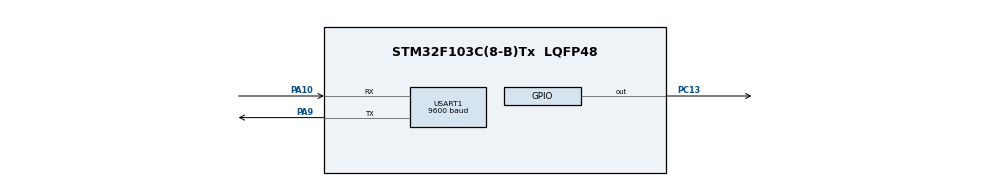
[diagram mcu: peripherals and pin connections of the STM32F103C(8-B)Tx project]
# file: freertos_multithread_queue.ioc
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FREERTOS.Tasks01=defaultTas,0,128,StartDefaultTask,Default,NULL,Dynamic,NULL,NULL
FREERTOS.configUSE_NEWLIB_REENTRANT=1
Mcu.Family=STM32F1
Mcu.Name=STM32F103C(8-B)Tx
Mcu.Package=LQFP48
NVIC.PriorityGroup=NVIC_PRIORITYGROUP_4
NVIC.USART1_IRQn=true\:5\:0\:false\:false\:true\:true\:true\:true\:true
PA10.Mode=Asynchronous
PA10.Signal=USART1_RX
PA13.Mode=Serial_Wire
PA13.Signal=SYS_JTMS-SWDIO
PA14.Mode=Serial_Wire
PA14.Signal=SYS_JTCK-SWCLK
PA9.Mode=Asynchronous
PA9.Signal=USART1_TX
PC13-TAMPER-RTC.Signal=GPIO_Output
ProjectManager.HeapSize=0x200
ProjectManager.StackSize=0x400
ProjectManager.TargetToolchain=STM32CubeIDE
RCC.APB1Freq_Value=8000000
RCC.APB2Freq_Value=8000000
USART1.BaudRate=9600
USART1.VirtualMode=VM_ASYNC
VP_FREERTOS_VS_CMSIS_V1.Mode=CMSIS_V1
board=custom

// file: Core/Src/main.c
/* USER CODE BEGIN Header */
/**
  ******************************************************************************
  * @file           : main.c
  * @brief          : Main program body
  ******************************************************************************
  * @attention
  *
  * Copyright (c) 2023 STMicroelectronics.
  * All rights reserved.
  *
  * This software is licensed under terms that can be found in the LICENSE file
  * in the root directory of this software component.
  * If no LICENSE file comes with this software, it is provided AS-IS.
  *
  ******************************************************************************
  */
/* USER CODE END Header */
#include "main.h"
#include "cmsis_os.h"
#include "usart.h"
#include "gpio.h"

/* USER CODE BEGIN Includes */
#include <string.h>
/* USER CODE END Includes */

/* USER CODE BEGIN PV */
volatile xQueueHandle serial_str_queue = NULL;
volatile xSemaphoreHandle serial_tx_wait_sem = NULL;
volatile xQueueHandle serial_rx_queue = NULL;

/* Queue structure used for passing messages. */
typedef struct
{
    char str[100];
} serial_str_msg;

/* Queue structure used for passing characters. */
typedef struct
{
    char ch;
} serial_ch_msg;

/* USER CODE END PV */

/* USER CODE BEGIN PFP */
void HAL_UART_TxCpltCallback(UART_HandleTypeDef *huart);
void HAL_UART_TxCpltCallback(UART_HandleTypeDef *huart);
void send_byte_rtos(char ch);
char receive_byte_rtos(void);
void led_flash_task( void *pvParameters );
void rs232_xmit_msg_task( void *pvParameters );
void queue_str_task(const char *str, int delay);
void queue_str_task1( void *pvParameters );
void queue_str_task2( void *pvParameters );
void serial_readwrite_task( void *pvParameters );

/* USER CODE END PFP */

int main(void)
{
  /* USER CODE BEGIN 1 */
	serial_ch_msg rx_msg;
  /* USER CODE END 1 */

  /* MCU Configuration--------------------------------------------------------*/

  /* Reset of all peripherals, Initializes the Flash interface and the Systick. */
  HAL_Init();

  /* Configure the system clock */
  SystemClock_Config();

  /* Initialize all configured peripherals */
  MX_GPIO_Init();
  MX_USART1_UART_Init();
  /* USER CODE BEGIN 2 */
  HAL_UART_Receive_IT(&huart1,(void *)&(rx_msg.ch), sizeof(rx_msg.ch));

  /* Create the queue to hold messages to be written to the RS232. */
  serial_str_queue = xQueueCreate( 10, sizeof( serial_str_msg ) );
  vSemaphoreCreateBinary(serial_tx_wait_sem);
  serial_rx_queue = xQueueCreate( 1, sizeof( serial_ch_msg ) );

  /* Create a task to flash the LED. */
  xTaskCreate( led_flash_task,"LED Flash", 256, NULL, tskIDLE_PRIORITY + 5, NULL );

  /* Create tasks to queue a string to be written to the RS232 port. */
  xTaskCreate( queue_str_task1, "Serial Write 1", 256 , NULL, tskIDLE_PRIORITY + 10, NULL );
  xTaskCreate( queue_str_task2, "Serial Write 2", 256 , NULL, tskIDLE_PRIORITY + 10, NULL );

  /* Create a task to write messages from the queue to the RS232 port. */
  xTaskCreate(rs232_xmit_msg_task, "Serial Xmit Str", 256 , NULL, tskIDLE_PRIORITY + 2, NULL );

  /* Create a task to receive characters from the RS232 port and echo them back to the RS232 port. */
  xTaskCreate(serial_readwrite_task, "Serial Read/Write", 256 ,NULL, tskIDLE_PRIORITY + 10, NULL );

  /* Start running the tasks. */
  vTaskStartScheduler();

  /* USER CODE END 2 */

  /* Infinite loop */
  while (1)
  {

  }
}

void SystemClock_Config(void)
{
  RCC_OscInitTypeDef RCC_OscInitStruct = {0};
  RCC_ClkInitTypeDef RCC_ClkInitStruct = {0};

  /** Initializes the RCC Oscillators according to the specified parameters
  * in the RCC_OscInitTypeDef structure.
  */
  RCC_OscInitStruct.OscillatorType = RCC_OSCILLATORTYPE_HSI;
  RCC_OscInitStruct.HSIState = RCC_HSI_ON;
  RCC_OscInitStruct.HSICalibrationValue = RCC_HSICALIBRATION_DEFAULT;
  RCC_OscInitStruct.PLL.PLLState = RCC_PLL_NONE;
  if (HAL_RCC_OscConfig(&RCC_OscInitStruct) != HAL_OK)
  {
    Error_Handler();
  }

  /** Initializes the CPU, AHB and APB buses clocks
  */
  RCC_ClkInitStruct.ClockType = RCC_CLOCKTYPE_HCLK|RCC_CLOCKTYPE_SYSCLK
                              |RCC_CLOCKTYPE_PCLK1|RCC_CLOCKTYPE_PCLK2;
  RCC_ClkInitStruct.SYSCLKSource = RCC_SYSCLKSOURCE_HSI;
  RCC_ClkInitStruct.AHBCLKDivider = RCC_SYSCLK_DIV1;
  RCC_ClkInitStruct.APB1CLKDivider = RCC_HCLK_DIV1;
  RCC_ClkInitStruct.APB2CLKDivider = RCC_HCLK_DIV1;

  if (HAL_RCC_ClockConfig(&RCC_ClkInitStruct, FLASH_LATENCY_0) != HAL_OK)
  {
    Error_Handler();
  }
}

/* USER CODE BEGIN 4 */
void HAL_UART_TxCpltCallback(UART_HandleTypeDef *huart)
{
   static signed portBASE_TYPE xHigherPriorityTaskWoken;
   //serial_ch_msg rx_msg;

   xSemaphoreGiveFromISR(serial_tx_wait_sem, &xHigherPriorityTaskWoken);

   if(xHigherPriorityTaskWoken)
   {
	 taskYIELD();
   }
}

void HAL_UART_RxCpltCallback(UART_HandleTypeDef *huart)
{
   static signed portBASE_TYPE xHigherPriorityTaskWoken;
   serial_ch_msg rx_msg;

   HAL_UART_Receive_IT(huart,(void *)&(rx_msg.ch), sizeof(rx_msg.ch));

   if(!xQueueSendToBackFromISR(serial_rx_queue, &rx_msg, &xHigherPriorityTaskWoken))
   {
	   /* If there was an error queueing the received byte, freeze. */
	   while(1);
   }

   if(xHigherPriorityTaskWoken)
   {
      taskYIELD();
   }
}

void send_byte_rtos(char ch)
{
    /* Wait until the RS232 port can receive another byte (this semaphore is
     * "given" by the RS232 port interrupt when the buffer has room for another
     * byte.
     */
	while(!xSemaphoreTake(serial_tx_wait_sem,100));
    //while(!xSemaphoreTake(serial_tx_wait_sem, HAL_MAX_DELAY));

    /* Send the byte and enable the transmit interrupt (it is disabled by the
     * interrupt).
     */
	HAL_UART_Transmit_IT(&huart1,(uint8_t *)&ch, sizeof(ch));
 }

char receive_byte_rtos(void)
{
    serial_ch_msg msg;

    /* Wait for a byte to be queued by the receive interrupt handler. */
    while(!xQueueReceive(serial_rx_queue, &msg, HAL_MAX_DELAY));

    return msg.ch;
}

void led_flash_task( void *pvParameters )
{
    while(1)
    {
        /* Toggle the LED. */

    	HAL_GPIO_TogglePin(GPIOC, GPIO_PIN_13);
		/* Wait one second. */
		vTaskDelay(1000);
    }
}

void rs232_xmit_msg_task( void *pvParameters )
{
    serial_str_msg msg;
    int curr_char;

    while(1) {
        /* Read from the queue.  Keep trying until a message is received.  This
         * will block for a period of time (specified by portMAX_DELAY). */
        while(!xQueueReceive(serial_str_queue, &msg, portMAX_DELAY));

        /* Write each character of the message to the RS232 port. */
        curr_char = 0;
        while(msg.str[curr_char] != '\0') {
            send_byte_rtos(msg.str[curr_char]);
            curr_char++;
        }
    }
}

/* Repeatedly queues a string to be sent to the RS232.
 *   delay - the time to wait between sending messages.  A delay of 1 means
 *           wait 1/100th of a second.
 */
void queue_str_task(const char *str, int delay)
{
    serial_str_msg msg;

    /* Prepare the message to be queued. */
    strcpy(msg.str, str);

    while(1) {
        /* Post the message.  Keep on trying until it is successful. */
        while(!xQueueSendToBack(serial_str_queue, &msg, portMAX_DELAY));

        /* Wait. */
        vTaskDelay(delay);
    }
}

void queue_str_task1( void *pvParameters )
{
    queue_str_task("Hola soy Tarea 1, probando ejecucion con FreeRTOS\r\n", 5000);
}

void queue_str_task2( void *pvParameters )
{
    queue_str_task("Hola soy Tarea 2, probando ejecucion con FreeRTOS\r\n", 5000);
}

void serial_readwrite_task( void *pvParameters )
{
    serial_str_msg msg;
    char ch;
    int curr_char;
    int done;

    /* Prepare the response message to be queued. */
    strcpy(msg.str, "RV: ");

    while(1) {
        curr_char = 4;
        done = 0;
        do {
            /* Receive a byte from the RS232 port (this call will block). */
            ch = receive_byte_rtos();

            /* If the byte is an end-of-line type character, then finish the
             * string and indicate we are done.
             */
            if((ch == '\r') || (ch == '\n')) {
                msg.str[curr_char] = '\n';
                msg.str[curr_char+1] = '\0';
                done = -1;
            /* Otherwise, add the character to the response string. */
            } else {
                msg.str[curr_char++] = ch;
            }
        } while(!done);

        /* Once we are done building the response string, queue the response to
         * be sent to the RS232 port.
         */
        while(!xQueueSendToBack(serial_str_queue, &msg, portMAX_DELAY));
    }
}

/* USER CODE END 4 */

void Error_Handler(void)
{
  __disable_irq();
  while (1)
  {
  }
}

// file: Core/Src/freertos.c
/* USER CODE BEGIN Header */
/**
  ******************************************************************************
  * File Name          : freertos.c
  * Description        : Code for freertos applications
  ******************************************************************************
  * @attention
  *
  * Copyright (c) 2023 STMicroelectronics.
  * All rights reserved.
  *
  * This software is licensed under terms that can be found in the LICENSE file
  * in the root directory of this software component.
  * If no LICENSE file comes with this software, it is provided AS-IS.
  *
  ******************************************************************************
  */
/* USER CODE END Header */

#include "FreeRTOS.h"
#include "task.h"
#include "main.h"
#include "cmsis_os.h"

osThreadId defaultTasHandle;

void StartDefaultTask(void const * argument);

void MX_FREERTOS_Init(void); /* (MISRA C 2004 rule 8.1) */

/* GetIdleTaskMemory prototype (linked to static allocation support) */
void vApplicationGetIdleTaskMemory( StaticTask_t **ppxIdleTaskTCBBuffer, StackType_t **ppxIdleTaskStackBuffer, uint32_t *pulIdleTaskStackSize );

/* USER CODE BEGIN GET_IDLE_TASK_MEMORY */
static StaticTask_t xIdleTaskTCBBuffer;
static StackType_t xIdleStack[configMINIMAL_STACK_SIZE];

void vApplicationGetIdleTaskMemory( StaticTask_t **ppxIdleTaskTCBBuffer, StackType_t **ppxIdleTaskStackBuffer, uint32_t *pulIdleTaskStackSize )
{
  *ppxIdleTaskTCBBuffer = &xIdleTaskTCBBuffer;
  *ppxIdleTaskStackBuffer = &xIdleStack[0];
  *pulIdleTaskStackSize = configMINIMAL_STACK_SIZE;
  /* place for user code */
}

void vApplicationStackOverflowHook( TaskHandle_t xTask, char *pcTaskName )
{
	int i=0;
	i++;

}

void vApplicationMallocFailedHook( void )
{
	int i=0;
	i++;

}
/* USER CODE END GET_IDLE_TASK_MEMORY */
